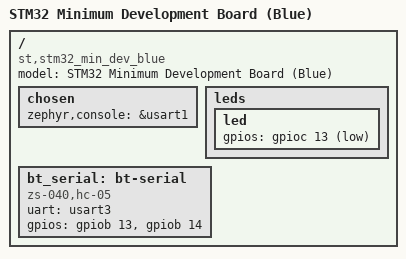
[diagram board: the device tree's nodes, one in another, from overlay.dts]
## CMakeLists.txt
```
# SPDX-License-Identifier: Apache-2.0

# For the sake of demonstration, we add the driver directory as a zephyr module
# by hand. If your driver is a project that's managed by west, you can remove this line.
list(APPEND ZEPHYR_EXTRA_MODULES
  ${CMAKE_CURRENT_SOURCE_DIR}/zs_040_module
)

cmake_minimum_required(VERSION 3.13.1)

find_package(Zephyr REQUIRED HINTS $ENV{ZEPHYR_BASE})
project(zs_040_driver)
target_sources(app PRIVATE
  src/main.c
  )
```

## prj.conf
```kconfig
CONFIG_SERIAL=y
CONFIG_UART_INTERRUPT_DRIVEN=y
CONFIG_ZS_040_DRIVER=y
CONFIG_APPLICATION_DEFINED_SYSCALL=y
```

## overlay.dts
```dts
/ {
	model = "STM32 Minimum Development Board (Blue)";
	compatible = "st,stm32_min_dev_blue", "st,stm32f103c8";
	chosen {
		zephyr,console = &usart1;
	};

	leds {
		led: led {
			gpios = <&gpioc 13 GPIO_ACTIVE_LOW>;
		};
	};

	bt_serial: bt-serial {
		compatible = "zs-040,hc-05";
		uart = <&usart3>;
		gpios = <&gpiob 13 GPIO_ACTIVE_HIGH>, <&gpiob 14 GPIO_ACTIVE_HIGH>;
	};
};
```

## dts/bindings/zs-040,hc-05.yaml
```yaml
# A high level description of the device the binding applies to:
description: |
   This is a device driver for the zs-040 hc-05 serial bluetooth modules

# Used to match nodes to this binding as discussed above:
compatible: "zs-040,hc-05"

properties:
  uart:
    type: phandle
    required: true
    description: GPIO pin configurations. We expect
        that the phandles will reference pinctrl nodes.
  gpios:
    type: phandle-array
    required: true
    description: State Pin
  
  # Requirements for and descriptions of the properties that this
  # binding's nodes need to satisfy go here.
```

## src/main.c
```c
/*
 * Copyright (c) 2019 Nordic Semiconductor
 *
 * SPDX-License-Identifier: Apache-2.0
 */

#include "zs_040_driver.h"
#include <stdio.h>
#include <zephyr.h>
#include <device.h>
#include <string.h>

int process_command(const struct device *dev, uint8_t * data, size_t len) {
	const struct zs_040_driver_api * zs_040_api = dev->api;
	struct zs_040_data_s *zs_040_data = dev->data;
	char *reply = "CMD_OK\r\n";

	if (ZS_040_CONNECTED_STATE == zs_040_data->state) {
		zs_040_api->send_at_command(dev, reply, strlen(reply));
	}

	return 0;
}

void main(void)
{
	const struct device *dev = device_get_binding("zs_040");
	const struct zs_040_driver_api * zs_040_api;
	
	zs_040_api = dev->api;

	if (!dev) {
		printk("Could not find zs_040 device\r\n");
	}

	zs_040_api->set_data_recv_cb(dev, process_command);

	while (1) {
		k_sleep(K_MSEC(1));
	}
}
```

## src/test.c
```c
//
//  uart_irq.c
//
//
//  Created by Barron Wong on 7/24/21.
//

#include "uart_irq.h"
#include <device.h>
#include <misc/printk.h>
#include <uart.h>
#include <zephyr.h>
#define SYS_LOG_DOMAIN "UART_DRIVER"
#include <logging/sys_log.h>

static void (*__uart_callback)(u8_t) = 0;
void ay_uart_driver_set_callback(void (*callback)(u8_t))
{
    __uart_callback = callback;
}
static void uart_fifo_callback(struct device *dev)
{
    u8_t recvData;
    /* Verify uart_irq_update() */
    if (!uart_irq_update(dev)) {
        SYS_LOG_ERR("retval should always be 1");
        return;
    }
    /* Verify uart_irq_rx_ready() */
    if (uart_irq_rx_ready(dev)) {
        /* Verify uart_fifo_read() */
        uart_fifo_read(dev, &recvData, 1);
        if (__uart_callback) {
            __uart_callback(recvData);
        }
    }
}

u8_t ay_uart_driver_open()
{
    struct device *uart_dev = device_get_binding("UART_0");
    if (!uart_dev) {
        SYS_LOG_ERR("Problem to load uart device");
        return 1;
    }
    
    /* Verify uart_irq_callback_set() */
    uart_irq_callback_set(uart_dev, uart_fifo_callback);
    /* Enable Tx/Rx interrupt before using fifo */
    /* Verify uart_irq_rx_enable() */
    uart_irq_rx_enable(uart_dev);
    SYS_LOG_INF("UART device loaded...[OK]");
    return 0;
}

void ay_uart_driver_write(u8_t data)
{
    
}
```
